# RN831X_RN861X_MCU register map
File version: v0.0.1
CPU: RN831X_RN861X_MCU r1p0, little endian, MPU, no FPU
Registers are 32-bit, read-write, reset 0x0 unless marked. A register's access mark holds for its fields unless they carry their own. Offsets are from the block's base; [hi:lo] are bit positions; {n}, {i} and the like mark numbered series; 'fields as' and 'values as' point back to an identical list.

## SYSTEM_CORE1 — SYSTEM Module core1
Base 0xA0080000
0x00 SYS_PSW1 access not given — Public Password Register
  [7:0] SYS_PSW1 — When SYS_PSW1 = 8'h82, public registers are writable.
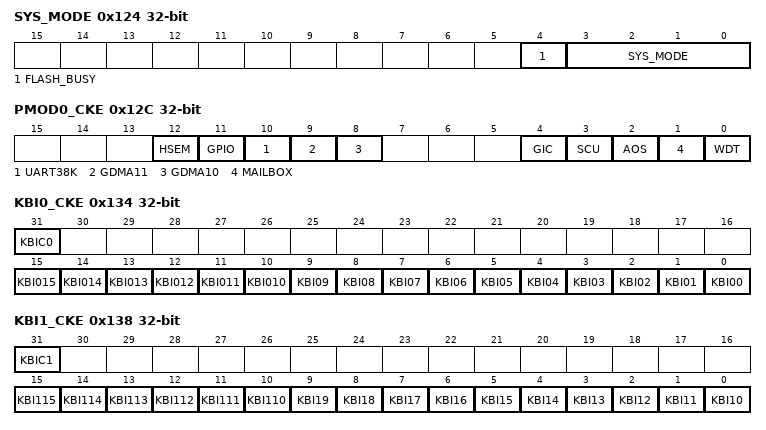
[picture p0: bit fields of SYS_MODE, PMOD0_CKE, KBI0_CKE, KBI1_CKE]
0x124 SYS_MODE ro — System Mode Register
  [4] FLASH_BUSY — Flash busy status
  [3:0] SYS_MODE — HCM/RC/LCM mode
    4=HCM (High-frequency mode HCM, read value 4'b0100); 2=RCM (RC mode RCM, read value 4'b0010); 1=LCM (32.768KHz mode LCM, read value 4'b0001)
0x12C PMOD0_CKE — Private Module Clock Enable Register
  [12] HSEM — HSEM module enable
  [11] GPIO — GPIO module enable
  [10] UART38K — UART38K module clock enable
  [9] GDMA11 — GDMA11 module clock enable
  [8] GDMA10 — GDMA10 module clock enable
  [4] GIC — CORE0_GIC module clock enable
  [3] SCU — CORE0_SCU module clock enable
  [2] AOS — CORE0_AOS module clock enable
  [1] MAILBOX — CORE0_MAILBOX module clock enable
  [0] WDT — CORE0_WDT APB clock enable
0x134 KBI0_CKE — KBI0 Clock Enable Register
  [31] KBIC0 — KBIC0 APB module clock enable
  [n] KBI{n:03} (n=10..15) — KBI{n:03} module clock enable
  [n] KBI{n:02} (n=0..9) — KBI{n:02} module clock enable
0x138 KBI1_CKE — KBI1 Clock Enable Register
  [31] KBIC1 — KBIC1 APB module clock enable
  [n-100] KBI{n} (n=110..115) — KBI{n} module clock enable
  [n-10] KBI{n} (n=10..19) — KBI{n-10:02} module clock enable
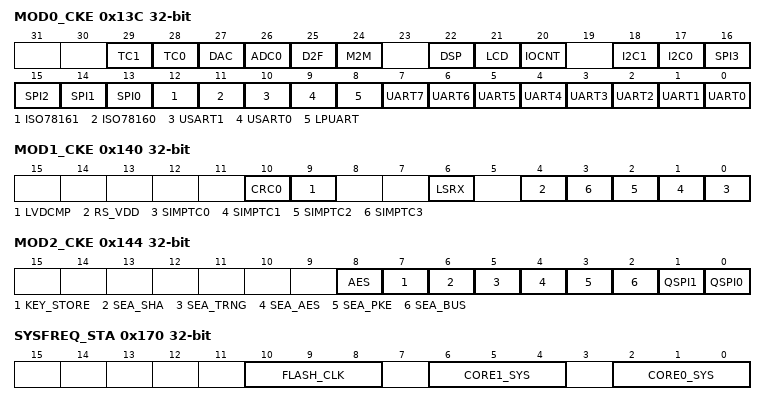
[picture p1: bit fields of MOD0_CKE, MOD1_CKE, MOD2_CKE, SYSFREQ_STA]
0x13C MOD0_CKE — Module Clock Enable Register 0
  [29] TC1 — TC1 module clock enable
  [28] TC0 — TC0 module clock enable
  [27] DAC — DAC module clock enable
  [26] ADC0 — ADC0 module clock enable
  [25] D2F — D2F module clock enable
  [24] M2M — M2M module clock enable
  [22] DSP — DSP module clock enable
  [21] LCD — LCD module clock enable
  [20] IOCNT — IOCNT module clock enable
  [18] I2C1 — I2C1 module clock enable
  [17] I2C0 — I2C0 module clock enable
  [n+13] SPI{n} (n=0..3) — SPI{n} module clock enable
  [12] ISO78161 — ISO7816_1 module clock enable
  [11] ISO78160 — ISO7816_0 module clock enable
  [10] USART1 — USART1 module clock enable
  [9] USART0 — USART0 module clock enable
  [8] LPUART — LPUART module clock enable
  [n] UART{n} (n=0..7) — UART{n} module clock enable
0x140 MOD1_CKE — Module Clock Enable Register 1
  [10] CRC0 — CRC0 Module Clock Enable
  [9] LVDCMP — LVDCMP Module Clock Enable
  [6] LSRX — LSRX Module Clock Enable
  [4] RS_VDD — RS_VDD Module Clock Enable
  [n] SIMPTC{n} (n=0..3) — SIMP_TC{n} Module Clock Enable
0x144 MOD2_CKE — Module Clock Enable Register 2
  [8] AES — AES Module Clock Enable
  [7] KEY_STORE — KEY_STORE Module Clock Enable
  [6] SEA_SHA — SEA_SHA Module Clock Enable
  [5] SEA_TRNG — SEA_TRNG Module Clock Enable
  [4] SEA_AES — SEA_AES Module Clock Enable
  [3] SEA_PKE — SEA_PKE Module Clock Enable
  [2] SEA_BUS — SEA_BUS Module Clock Enable
  [1] QSPI1 — QSPI1 Module Clock Enable
  [0] QSPI0 — QSPI0 Module Clock Enable
0x170 SYSFREQ_STA ro — System Clock Frequency Indication Register
  [10:8] FLASH_CLK — Flash System Frequency Indication
    0=32K768 (Current system main clock is 32.768KHz); 1=1M8432 (Current system main clock is 1.8432MHz); 2=3M6864 (Current system main clock is 3.6864MHz); 3=7M3728 (Current system main clock is 7.3728MHz); 4=14M7456 (Current system main clock is 14.7456MHz); 5=29M4912 (Current system main clock is 29.4912MHz); 6=58M9824 (Current system main clock is 58.9824MHz)
  [6:4] CORE1_SYS — CORE1 System Main Clock Frequency Indication
    values as FLASH_CLK
  [2:0] CORE0_SYS — CORE0 System Main Clock Frequency Indication
    0=32K768 (Current system main clock is 32.768KHz); 1=1M8432 (Current system main clock is 1.8432MHz); 2=3M6864 (Current system main clock is 3.6864MHz); 3=7M3728 (Current system main clock is 7.3728MHz); 4=14M7456 (Current system main clock is 14.7456MHz); 5=29M4912 (Current system main clock is 29.4912MHz)
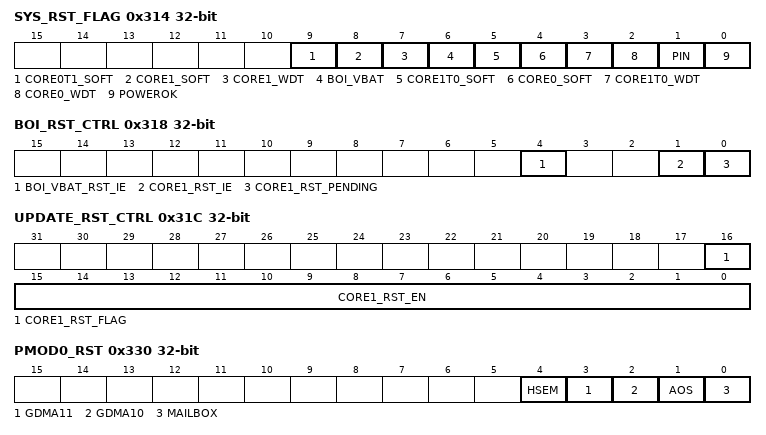
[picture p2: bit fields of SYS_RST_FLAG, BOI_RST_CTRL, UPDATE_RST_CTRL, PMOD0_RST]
0x314 SYS_RST_FLAG — System Reset Flag Register
  [9] CORE0T1_SOFT write-1-clears — CORE0T1 Software Reset Flag
  [8] CORE1_SOFT write-1-clears — CORE1 Software Reset Flag
  [7] CORE1_WDT write-1-clears — CORE1 WDT Reset Flag
  [6] BOI_VBAT write-1-clears — VBAT BOI Power-Down Reset Occurred
  [5] CORE1T0_SOFT write-1-clears — CORE1T0 Software Reset Flag
  [4] CORE0_SOFT write-1-clears — CORE0 Software Reset Flag
  [3] CORE1T0_WDT write-1-clears — CORE1T0 WDT Reset Flag
  [2] CORE0_WDT write-1-clears — CORE0 WDT Reset Flag
  [1] PIN write-1-clears — External Pin Reset Flag
  [0] POWEROK write-1-clears — Power Reset Flag
0x318 BOI_RST_CTRL — BOI_VBAT Reset Control Register
  [4] BOI_VBAT_RST_IE — BOI_VBAT_RST Interrupt Enable
  [1] CORE1_RST_IE — Core1 Reset Enable
  [0] CORE1_RST_PENDING write-1-clears — Core1 Reset Flag
0x31C UPDATE_RST_CTRL — Update Reset Control Register
  [16] CORE1_RST_FLAG write-1-clears — CORE0 Update Reset Flag
  [15:0] CORE1_RST_EN — CORE0 Update Reset Enable
0x330 PMOD0_RST — CORE0 Private Module Reset Register
  [4] HSEM — Software reset HSEM module
  [3] GDMA11 — Software reset GDMA11 module
  [2] GDMA10 — Software reset GDMA10 module
  [1] AOS — Software reset AOS module
  [0] MAILBOX — Software reset MAILBOX module
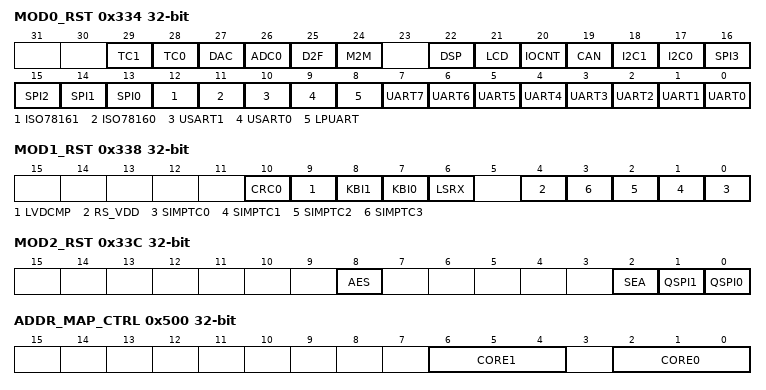
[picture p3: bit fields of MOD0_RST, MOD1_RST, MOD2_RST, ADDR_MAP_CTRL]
0x334 MOD0_RST — Assignable Module 0 Reset Register
  [29] TC1 — Software reset TC1 module
  [28] TC0 — Software reset TC0 module
  [27] DAC — Software reset DAC module
  [26] ADC0 — Software reset ADC0 module
  [25] D2F — Software reset D2F module
  [24] M2M — Software reset M2M module
  [22] DSP — Software reset DSP module
  [21] LCD — Software reset LCD module
  [20] IOCNT — Software reset IOCNT module
  [19] CAN — Software reset CAN module
  [18] I2C1 — Software reset I2C1 module
  [17] I2C0 — Software reset I2C0 module
  [n+13] SPI{n} (n=0..3) — Software reset SPI{n} module
  [12] ISO78161 — Software reset ISO78161 module
  [11] ISO78160 — Software reset ISO78160 module
  [10] USART1 — Software reset USART1 module
  [9] USART0 — Software reset USART0 module
  [8] LPUART — Software reset LPUART module
  [n] UART{n} (n=0..7) — Software reset UART{n} module
0x338 MOD1_RST — Assignable Module 1 Reset Register
  [10] CRC0 — Software reset CRC0 module
  [9] LVDCMP — Software reset LVDCMP module
  [8] KBI1 — Software reset KBI1 module
  [7] KBI0 — Software reset KBI0 module
  [6] LSRX — Software reset LSRX module
  [4] RS_VDD — Software reset RS_VDD module
  [n] SIMPTC{n} (n=0..3) — Software reset SIMP_TC{n} module
0x33C MOD2_RST — Assignable Module 2 Reset Register
  [8] AES — Software reset AES module
  [2] SEA — Software reset SEA module
  [1] QSPI1 — Software reset QSPI1 module
  [0] QSPI0 — Software reset QSPI0 module
0x500 ADDR_MAP_CTRL access per field — Address Mapping Control Register
  [6:4] CORE1 rw — Core1 Address ReMapping
    0=CORE1 FLASH mapped to address 0x8000_0000; 1=CORE1 FLASH mapped to address 0x9000_0000; 2=CORE1 FLASH mapped to address 0x8100_0000
  [2:0] CORE0 ro — Core0 Address ReMapping
    0=CORE0 FLASH mapped to address 0x0020_0000; 1=CORE0 FLASH mapped to address 0x0000_0000; 2=CORE0 FLASH mapped to address 0x1020_0000
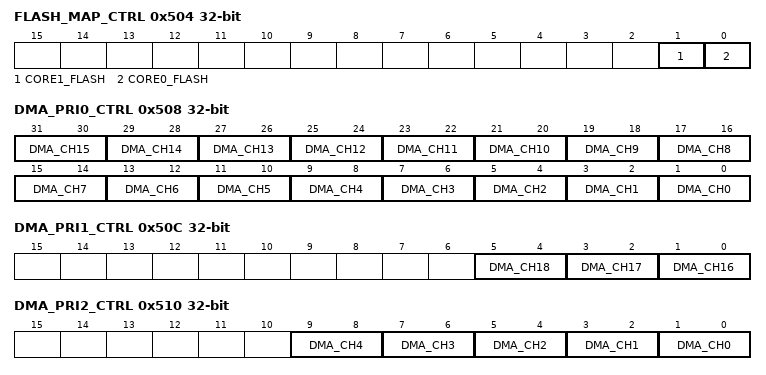
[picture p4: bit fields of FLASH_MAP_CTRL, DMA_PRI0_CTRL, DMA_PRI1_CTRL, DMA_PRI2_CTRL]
0x504 FLASH_MAP_CTRL access per field — FLASH Mapping Control Register
  [1] CORE1_FLASH rw — Core1 Flash Address Mapping
  [0] CORE0_FLASH ro — Core0 Flash Address Mapping
0x508 DMA_PRI0_CTRL — DMA Access SRAM Priority Configuration Register 0
  [31:30] DMA_CH15 — Channel 15: TCO_PWM channel access SRAM priority configuration.
  [29:28] DMA_CH14 — Channel 14: CAN channel access SRAM priority configuration.
  [2n+1:2n] DMA_CH{n} (n=6..13) — Channel {n}: UART{n-6} channel access SRAM priority configuration.
  [11:10] DMA_CH5 — Channel 5: DAC channel access SRAM priority configuration.
  [9:8] DMA_CH4 — Channel 4: SARADC channel access SRAM priority configuration.
  [2n+1:2n] DMA_CH{n} (n=0..3) — Channel {n}: SPI{n} channel access SRAM priority configuration.
0x50C DMA_PRI1_CTRL — DMA Access SRAM Priority Configuration Register 1
  [5:4] DMA_CH18 — Channel 18: M2M channel access SRAM priority configuration.
  [3:2] DMA_CH17 — Channel 17: AES channel access SRAM priority configuration.
  [1:0] DMA_CH16 — Channel 16: TC1_PWM channel access SRAM priority configuration.
0x510 DMA_PRI2_CTRL — DMA Access SRAM Priority Configuration Register 2
  [9:8] DMA_CH4 — Channel 4: CORE0/CORE1 channel access SRAM priority configuration.
  [7:6] DMA_CH3 — Channel 3: DSP channel access SRAM priority configuration.
  [5:4] DMA_CH2 — Channel 2: General DMA write channel (MDMA0x_WR/MDMA1x_WR) access SRAM priority configuration.
  [3:2] DMA_CH1 — Channel 1: General DMA read channel (MDMA0x_RD/MDMA1x_RD) access SRAM priority configuration.
  [1:0] DMA_CH0 — Channel 0: First level arbitration result channel access SRAM priority configuration.
0x51C CORE1_STA 33-bit access not given — Core1 STOP status registers
  [0] CORE1_STOP_FLAG — Core1 STOP State Indication
0x800 CHIP_ID access not given
  [15:0] CHIP_ID — CHIP_ID: C248
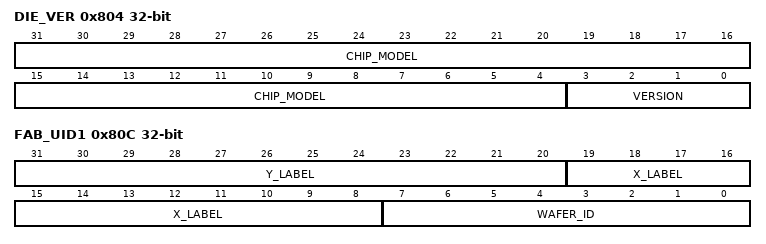
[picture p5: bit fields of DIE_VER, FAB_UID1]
0x804 DIE_VER ro — Chip Version Register
  [31:4] CHIP_MODEL — Chip Model: A9701C, Encoded in ASCII
  [3:0] VERSION — Version Number
0x808 FAB_UID0 access not given — Chip Unique ID 0 Register
  [31:0] LOT_NUM — This register is configured by the bootloader
0x80C FAB_UID1 ro — Chip Unique ID 1 Register
  [31:20] Y_LABEL — DIE Y-coordinate
  [19:8] X_LABEL — DIE X-coordinate
  [7:0] WAFER_ID — the wafer WAFER ID information
